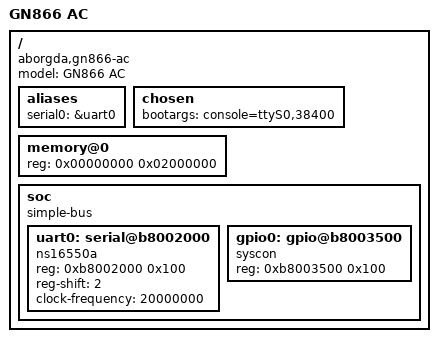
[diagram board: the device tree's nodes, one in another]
/dts-v1/;

/ {
  compatible = "aborgda,gn866-ac", "realtek,rtl8198c";
  model = "GN866 AC";

  aliases {
    serial0 = &uart0;
  };

  chosen {
    bootargs = "console=ttyS0,38400";
  };

  memory@0 {
    device_type = "memory";
    reg = <0x00000000 0x02000000>;
  };

  soc {
    compatible = "simple-bus";
    #address-cells = <1>;
    #size-cells = <1>;
    ranges;

    uart0: serial@b8002000 {
      compatible = "ns16550a";
      reg = <0xb8002000 0x100>;
      reg-shift = <2>;
      clock-frequency = <20000000>;
      status = "okay";
    };

    gpio0: gpio@b8003500 {
      compatible = "syscon";
      reg = <0xb8003500 0x100>;
      status = "okay";
    };
  };
};
